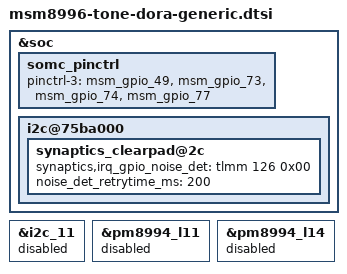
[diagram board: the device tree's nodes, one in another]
/* Copyright (c) 2015, The Linux Foundation. All rights reserved.
 * This program is free software; you can redistribute it and/or modify
 * it under the terms of the GNU General Public License version 2 and
 * only version 2 as published by the Free Software Foundation.
 *
 * This program is distributed in the hope that it will be useful,
 * but WITHOUT ANY WARRANTY; without even the implied warranty of
 * MERCHANTABILITY or FITNESS FOR A PARTICULAR PURPOSE.  See the
 * GNU General Public License for more details.
 */
/*
 * Copyright (C) 2016 Sony Mobile Communications Inc.
 *
 * This program is free software; you can redistribute it and/or modify
 * it under the terms of the GNU General Public License version 2, as
 * published by the Free Software Foundation.
 */

&soc {
	somc_pinctrl: somc_pinctrl {
		/* If variant specific default setting is needed,
		   fill pinctrl-3 value in <variant>.dtsi */
		pinctrl-3 = <&msm_gpio_49 &msm_gpio_73 &msm_gpio_74
				&msm_gpio_77>;
	};

	/* I2C : BLSP12 */
	i2c@75ba000 {
		synaptics_clearpad@2c {
			synaptics,irq_gpio_noise_det = <&tlmm 126 0x00>;
			noise_det_retrytime_ms = <200>;
		};
	};
};

/* I2C : BLSP11 */
&i2c_11 {
	status = "disabled";
};

/* Regulator config */
&pm8994_l11 {
	status = "disabled";
};

&pm8994_l14 {
	status = "disabled";
};
